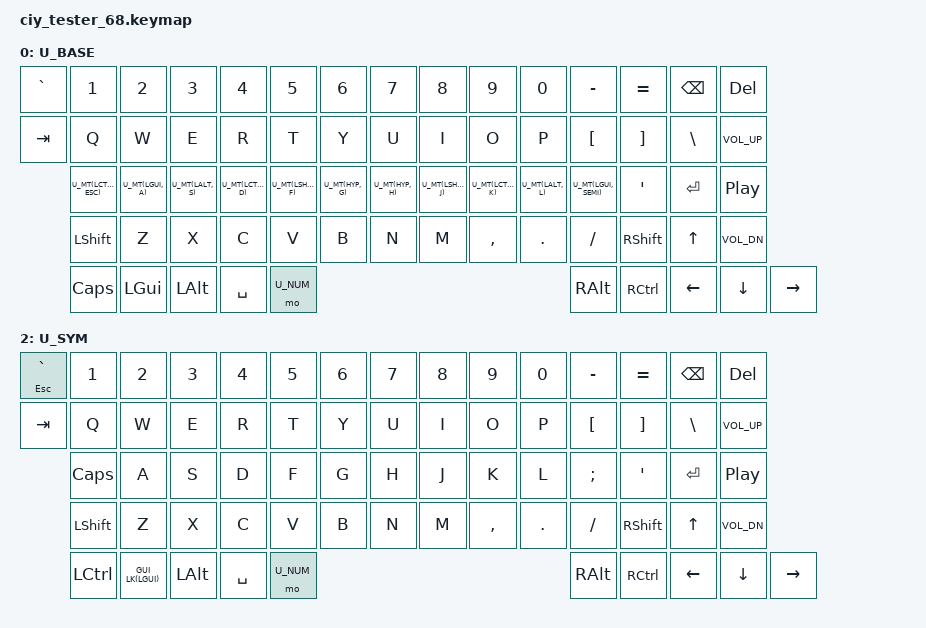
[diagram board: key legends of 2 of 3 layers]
#include <behaviors.dtsi>

#include <dt-bindings/zmk/keys.h>
#include <dt-bindings/zmk/bt.h>
#include <dt-bindings/zmk/outputs.h>
#include <dt-bindings/zmk/pointing.h>
#include <dt-bindings/zmk/ext_power.h>

#include "../../../miryoku/constants.h"
#include "../../../miryoku/macros.dtsi"
#include "../../../miryoku/behaviors/behaviors.dtsi"
#include "../../../miryoku/layers/layers.h"
#include "../../../miryoku/combos/ciy/combos.dtsi"
#include "../../../miryoku/mouse/mouse.h"
// ┌───┬───┬───┬───┬───┬───╥───┬───┬───┬───┬───┬───┬───┬───────┬───┐
// │   │   │   │   │   │   ║   │   │   │   │   │   │   │       │   │
// ├───┴─┬─┴─┬─┴─┬─┴─┬─┴─┬─╨─╥─┴─┬─┴─┬─┴─┬─┴─┬─┴─┬─┴─┬─┴─┬─────┼───┤
// │     │   │   │   │   │   ║   │   │   │   │   │   │   │     │   │
// ├─────┴┬──┴┬──┴┬──┴┬──┴┬──╨╥──┴┬──┴┬──┴┬──┴┬──┴┬──┴┬──┴─────┼───┤
// │      │   │   │   │   │   ║   │   │   │   │   │   │        │   │
// ├──────┴─┬─┴─┬─┴─┬─┴─┬─┴─┬─╨─╥─┴─┬─┴─┬─┴─┬─┴─┬─┴─┬─┴────┬───┼───┤
// │        │   │   │   │   │   ║   │   │   │   │   │      │   │   │
// ├────┬───┴┬──┴─┬─┴───┴───┴───╨───┴───┴──┬┴──┬┴──┬┴──┬───┼───┼───┤
// │    │    │    │                        │   │   │   │   │   │   │
// └────┴────┴────┴────────────────────────┴───┴───┴───┴───┴───┴───┘

/ {
    keymap {
        compatible = "zmk,keymap";

// ┌───┬───┬───┬───┬───┬───┬───┬───┬───┬───┬───┬───┬───┬───────┬───┐
// │ ` │ 1 │ 2 │ 3 │ 4 │ 5 │ 6 │ 7 │ 8 │ 9 │ 0 │ - │ = │  BACK │DL │
// ├───┴─┬─┴─┬─┴─┬─┴─┬─┴─┬─┴─┬─┴─┬─┴─┬─┴─┬─┴─┬─┴─┬─┴─┬─┴─┬─────┼───┤
// │ TAB │ Q │ W │ E │ R │ T │ Y │ U │ I │ O │ P │ [ │ ] │  \  │V+ │
// ├─────┴┬──┴┬──┴┬──┴┬──┴┬──┴┬──┴┬──┴┬──┴┬──┴┬──┴┬──┴┬──┴─────┼───┤
// │ CAPS │ A │ S │ D │ F │ G │ H │ J │ K │ L │ ; │ ' │ ENTER  │PP │
// ├──────┴─┬─┴─┬─┴─┬─┴─┬─┴─┬─┴─┬─┴─┬─┴─┬─┴─┬─┴─┬─┴─┬─┴────┬───┼───┤
// │ SHIFT  │ Z │ X │ C │ V │ B │ N │ M │ , │ . │ / │SHIFT │UP │V- │
// ├────┬───┴┬──┴─┬─┴───┴───┴───┴───┴───┴──┬┴──┬┴──┬┴──┬───┼───┼───┤
// │CTRL│GUI │ALT │         SPACE          │MOD│ALT│CTL│LFT│DWN│RGT│
// └────┴────┴────┴────────────────────────┴───┴───┴───┴───┴───┴───┘
        U_BASE {
            bindings = <
                &kp GRAVE  &kp N1    &kp N2   &kp N3   &kp N4 &kp N5 &kp N6    &kp N7 &kp N8 &kp N9    &kp N0   &kp MINUS &kp EQUAL &kp BSPC &kp DEL
                &kp TAB        &kp Q     &kp W    &kp E    &kp R  &kp T  &kp Y     &kp U  &kp I  &kp O     &kp P    &kp LBKT  &kp RBKT  &kp BSLH &kp C_VOL_UP
                               U_MT(LCTRL, ESC) U_MT(LGUI, A)     U_MT(LALT, S) U_MT(LCTRL, D)     U_MT(LSHFT, F)     U_MT(HYP, G)               U_MT(HYP, H)            U_MT(LSHFT, J)     U_MT(LCTRL, K)    U_MT(LALT, L)   U_MT(LGUI, SEMI) &kp SQT   &kp RET  &kp C_PP
                               &kp LSHFT &kp Z    &kp X    &kp C  &kp V  &kp B     &kp N  &kp M  &kp COMMA &kp DOT  &kp FSLH  &kp RSHFT &kp UP   &kp C_VOL_DN
                               &kp CAPS &kp LGUI &kp LALT               &kp SPACE               &mo U_NUM     &kp RALT &kp RCTRL &kp LEFT  &kp DOWN &kp RIGHT
            >;
        };


// ┌───┬───┬───┬───┬───┬───┬───┬───┬───┬───┬───┬───┬───┬───────┬───┐
// │USB│F1 │F2 │F3 │F4 │F5 │F6 │F7 │F8 │F9 │F10│F11│F12│ BACK  │BTL│
// ├───┴─┬─┴─┬─┴─┬─┴─┬─┴─┬─┴─┬─┴─┬─┴─┬─┴─┬─┴─┬─┴─┬─┴─┬─┴─┬─────┼───┤
// │BTCLR│MB4│MB1│MUP│MB2│MB5│ Y │ U │ I │ O │ P │ [ │ ] │ALTAB│B+ │
// ├─────┴┬──┴┬──┴┬──┴┬──┴┬──┴┬──┴┬──┴┬──┴┬──┴┬──┴┬──┴┬──┴─────┼───┤
// │ RST  │MWL│MLT│MDN│MRT│MWR│HOM│LFT│UP │DWN│RGT│END│ ENTER  │BAT│
// ├──────┴─┬─┴─┬─┴─┬─┴─┬─┴─┬─┴─┬─┴─┬─┴─┬─┴─┬─┴─┬─┴─┬─┴────┬───┼───┤
// │ SHIFT  │BT0│BT1│BT2│BT3│BT4│MWL│MWD│MWU│MWR│ / │SHIFT │PGU│B- │
// ├────┬───┴┬──┴─┬─┴───┴───┴───┴───┴───┴──┬┴──┬┴──┬┴──┬───┼───┼───┤
// │BLE │GUI │ALT │         SPACE          │MOD│ALT│CTL│HOM│PGD│GME│
// └────┴────┴────┴────────────────────────┴───┴───┴───┴───┴───┴───┘
        U_NUM {
            bindings = <
                &out OUT_USB &kp F1       &kp F2       &kp F3       &kp F4       &kp F5       &kp F6   &kp F7   &kp F8 &kp F9    &kp F10 &kp F11 &kp F12   &trans         &bootloader
                &bt BT_CLR   U_BTN4       U_BTN1       U_MS_U     U_BTN2       U_BTN5       &trans   &trans   &trans &trans    &trans  &trans  &trans    &kp LA(TAB)    &kp C_BRI_UP
                &sys_reset   U_WH_L       U_MS_L     U_MS_D     U_MS_R     U_WH_R       &kp LEFT &kp DOWN &kp UP &kp RIGHT &trans  &trans  &trans    &kp C_BRI_AUTO
                &trans       &u_bt_sel_0 &u_bt_sel_1 &u_bt_sel_2 &u_bt_sel_3 &u_bt_sel_4 U_WH_L   U_WH_D   U_WH_U U_WH_R    &trans  &trans  &kp PG_UP &kp C_BRI_DN
                &out OUT_BLE &trans       &trans                          &trans              &trans   &trans   &trans &kp HOME  &kp PG_DN                                &to U_SYM
            >;
        };

        U_SYM {
            bindings = <
                &mt ESC GRAVE  &kp N1    &kp N2      &kp N3   &kp N4 &kp N5 &kp N6    &kp N7 &kp N8 &kp N9    &kp N0   &kp MINUS &kp EQUAL &kp BSPC &kp DEL
                &kp TAB        &kp Q     &kp W       &kp E    &kp R  &kp T  &kp Y     &kp U  &kp I  &kp O     &kp P    &kp LBKT  &kp RBKT  &kp BSLH &kp C_VOL_UP
                               &kp CAPS  &kp A       &kp S    &kp D  &kp F  &kp G     &kp H  &kp J  &kp K     &kp L    &kp SEMI  &kp SQT   &kp RET  &kp C_PP
                               &kp LSHFT &kp Z       &kp X    &kp C  &kp V  &kp B     &kp N  &kp M  &kp COMMA &kp DOT  &kp FSLH  &kp RSHFT &kp UP   &kp C_VOL_DN
                               &kp LCTRL GUI_LK(LGUI) &kp LALT               &kp SPACE               &mo U_NUM     &kp RALT &kp RCTRL &kp LEFT  &kp DOWN &kp RIGHT
            >;
        };
    };
};
